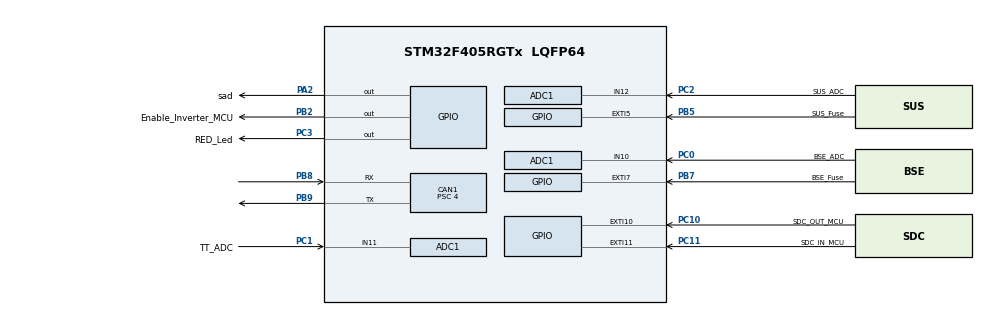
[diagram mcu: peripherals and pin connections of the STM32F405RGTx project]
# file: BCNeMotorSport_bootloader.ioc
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ADC1.Channel-0\#ChannelRegularConversion=ADC_CHANNEL_12
ADC1.Channel-1\#ChannelRegularConversion=ADC_CHANNEL_11
ADC1.Channel-2\#ChannelRegularConversion=ADC_CHANNEL_10
ADC1.ClockPrescaler=ADC_CLOCK_SYNC_PCLK_DIV4
ADC1.ContinuousConvMode=DISABLE
ADC1.DMAContinuousRequests=ENABLE
ADC1.EOCSelection=ADC_EOC_SEQ_CONV
ADC1.ExternalTrigConv=ADC_EXTERNALTRIGCONV_T2_TRGO
ADC1.ExternalTrigConvEdge=ADC_EXTERNALTRIGCONVEDGE_RISINGFALLING
ADC1.NbrOfConversion=3
ADC1.NbrOfConversionFlag=1
ADC1.Rank-0\#ChannelRegularConversion=1
ADC1.Rank-1\#ChannelRegularConversion=2
ADC1.Rank-2\#ChannelRegularConversion=3
ADC1.Resolution=ADC_RESOLUTION_12B
ADC1.SamplingTime-0\#ChannelRegularConversion=ADC_SAMPLETIME_56CYCLES
ADC1.SamplingTime-1\#ChannelRegularConversion=ADC_SAMPLETIME_56CYCLES
ADC1.SamplingTime-2\#ChannelRegularConversion=ADC_SAMPLETIME_56CYCLES
ADC1.master=1
CAN1.BS1=CAN_BS1_5TQ
CAN1.BS2=CAN_BS2_2TQ
CAN1.CalculateBaudRate=250000
CAN1.CalculateTimeBit=4000
CAN1.CalculateTimeQuantum=500.0
CAN1.Prescaler=4
CAN1.SJW=CAN_SJW_2TQ
Dma.ADC1.0.Direction=DMA_PERIPH_TO_MEMORY
Dma.ADC1.0.FIFOMode=DMA_FIFOMODE_DISABLE
Dma.ADC1.0.Instance=DMA2_Stream0
Dma.ADC1.0.MemDataAlignment=DMA_MDATAALIGN_WORD
Dma.ADC1.0.MemInc=DMA_MINC_ENABLE
Dma.ADC1.0.Mode=DMA_CIRCULAR
Dma.ADC1.0.PeriphDataAlignment=DMA_PDATAALIGN_WORD
Dma.ADC1.0.PeriphInc=DMA_PINC_DISABLE
Dma.ADC1.0.Priority=DMA_PRIORITY_LOW
Dma.Request0=ADC1
Mcu.Family=STM32F4
Mcu.Name=STM32F405RGTx
Mcu.Package=LQFP64
NVIC.ADC_IRQn=true\:0\:0\:false\:false\:true\:true\:true\:true
NVIC.CAN1_RX0_IRQn=true\:0\:0\:false\:false\:true\:true\:true\:true
NVIC.CAN1_RX1_IRQn=true\:0\:0\:false\:false\:true\:true\:true\:true
NVIC.CAN1_SCE_IRQn=true\:0\:0\:false\:false\:true\:true\:true\:true
NVIC.CAN1_TX_IRQn=true\:0\:0\:false\:false\:true\:true\:true\:true
NVIC.DMA2_Stream0_IRQn=true\:0\:0\:false\:false\:true\:false\:true\:true
NVIC.EXTI15_10_IRQn=true\:0\:0\:false\:false\:true\:true\:true\:true
NVIC.PriorityGroup=NVIC_PRIORITYGROUP_4
NVIC.RCC_IRQn=true\:0\:0\:false\:false\:true\:true\:false\:true
NVIC.TIM2_IRQn=true\:0\:0\:false\:false\:true\:true\:true\:true
PA13.Mode=Serial_Wire
PA13.Signal=SYS_JTMS-SWDIO
PA14.Mode=Serial_Wire
PA14.Signal=SYS_JTCK-SWCLK
PA2.GPIO_Label=sad
PA2.Signal=GPIO_Output
PB2.GPIO_Label=Enable_Inverter_MCU
PB2.Signal=GPIO_Output
PB5.GPIO_Label=SUS_Fuse
PB5.GPIO_ModeDefaultEXTI=GPIO_MODE_IT_RISING_FALLING
PB5.Signal=GPXTI5
PB7.GPIO_Label=BSE_Fuse
PB7.GPIO_ModeDefaultEXTI=GPIO_MODE_IT_RISING_FALLING
PB7.Signal=GPXTI7
PB8.Mode=CAN_Activate
PB8.Signal=CAN1_RX
PB9.Mode=CAN_Activate
PB9.Signal=CAN1_TX
PC0.GPIO_Label=BSE_ADC
PC0.Signal=ADCx_IN10
PC1.GPIO_Label=TT_ADC
PC1.Signal=ADCx_IN11
PC10.GPIO_Label=SDC_OUT_MCU
PC10.GPIO_ModeDefaultEXTI=GPIO_MODE_IT_RISING_FALLING
PC10.Signal=GPXTI10
PC11.GPIO_Label=SDC_IN_MCU
PC11.GPIO_ModeDefaultEXTI=GPIO_MODE_IT_RISING_FALLING
PC11.Signal=GPXTI11
PC2.GPIO_Label=SUS_ADC
PC2.Signal=ADCx_IN12
PC3.GPIO_Label=RED_Led
PC3.Signal=GPIO_Output
PH0-OSC_IN.Signal=RCC_OSC_IN
PH1-OSC_OUT.Signal=RCC_OSC_OUT
ProjectManager.HeapSize=0x200
ProjectManager.StackSize=0x400
ProjectManager.TargetToolchain=STM32CubeIDE
RCC.48MHZClocksFreq_Value=25600000
RCC.AHBFreq_Value=16000000
RCC.APB1CLKDivider=RCC_HCLK_DIV2
RCC.APB1Freq_Value=8000000
RCC.APB1TimFreq_Value=16000000
RCC.APB2CLKDivider=RCC_HCLK_DIV4
RCC.APB2Freq_Value=4000000
RCC.APB2TimFreq_Value=8000000
RCC.CortexFreq_Value=16000000
RCC.HCLKFreq_Value=16000000
RCC.HSE_VALUE=20000000
RCC.HSI_VALUE=16000000
RCC.LSE_VALUE=32768
RCC.PLLM=10
RCC.PLLN=64
RCC.SYSCLKFreq_VALUE=16000000
RCC.VCOOutputFreq_Value=102400000
SH.ADCx_IN10.0=ADC1_IN10,IN10
SH.ADCx_IN11.0=ADC1_IN11,IN11
SH.ADCx_IN12.0=ADC1_IN12,IN12
TIM2.Channel-Output\ Compare1\ No\ Output=TIM_CHANNEL_1
TIM2.Period=15
TIM2.Prescaler=79
TIM2.TIM_MasterOutputTrigger=TIM_TRGO_UPDATE
VP_TIM2_VS_ClockSourceINT.Mode=Internal
VP_TIM2_VS_no_output1.Mode=Output Compare1 No Output
board=custom

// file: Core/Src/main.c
/* USER CODE BEGIN Header */
/**
  ******************************************************************************
  * @file           : main.c
  * @brief          : Main program body
  ******************************************************************************
  * @attention
  *
  * Copyright (c) 2025 STMicroelectronics.
  * All rights reserved.
  *
  * This software is licensed under terms that can be found in the LICENSE file
  * in the root directory of this software component.
  * If no LICENSE file comes with this software, it is provided AS-IS.
  *
  ******************************************************************************
  */
/* USER CODE END Header */
#include "main.h"

/* USER CODE BEGIN Includes */
#include "boot.h"
/* USER CODE END Includes */

CAN_HandleTypeDef hcan1;

void SystemClock_Config(void);
static void MX_GPIO_Init(void);
static void MX_DMA_Init(void);
static void MX_ADC1_Init(void);
static void MX_CAN1_Init(void);
static void MX_TIM2_Init(void);

int main(void)
{

  /* MCU Configuration--------------------------------------------------------*/

  /* Reset of all peripherals, Initializes the Flash interface and the Systick. */
  HAL_Init();

  /* Configure the system clock */
  SystemClock_Config();

  /* Initialize all configured peripherals */
  MX_GPIO_Init();
  MX_DMA_Init();
  MX_ADC1_Init();
  MX_CAN1_Init();
  MX_TIM2_Init();
  /* USER CODE BEGIN 2 */
  BootInit();
  /* USER CODE END 2 */

  /* Infinite loop */
  /* USER CODE BEGIN WHILE */
  while (1)
  {
	  BootTask();

    /* USER CODE END WHILE */

  }
}

void SystemClock_Config(void)
{
  LL_FLASH_SetLatency(LL_FLASH_LATENCY_0);
  while(LL_FLASH_GetLatency()!= LL_FLASH_LATENCY_0)
  {
  }
  LL_PWR_SetRegulVoltageScaling(LL_PWR_REGU_VOLTAGE_SCALE1);
  LL_RCC_HSI_SetCalibTrimming(16);
  LL_RCC_HSI_Enable();

   /* Wait till HSI is ready */
  while(LL_RCC_HSI_IsReady() != 1)
  {

  }
  LL_RCC_SetAHBPrescaler(LL_RCC_SYSCLK_DIV_1);
  LL_RCC_SetAPB1Prescaler(LL_RCC_APB1_DIV_2);
  LL_RCC_SetAPB2Prescaler(LL_RCC_APB2_DIV_4);
  LL_RCC_SetSysClkSource(LL_RCC_SYS_CLKSOURCE_HSI);

   /* Wait till System clock is ready */
  while(LL_RCC_GetSysClkSource() != LL_RCC_SYS_CLKSOURCE_STATUS_HSI)
  {

  }
  LL_SetSystemCoreClock(16000000);

   /* Update the time base */
  if (HAL_InitTick (TICK_INT_PRIORITY) != HAL_OK)
  {
    Error_Handler();
  }
}

static void MX_ADC1_Init(void)
{

  LL_ADC_InitTypeDef ADC_InitStruct = {0};
  LL_ADC_REG_InitTypeDef ADC_REG_InitStruct = {0};
  LL_ADC_CommonInitTypeDef ADC_CommonInitStruct = {0};

  LL_GPIO_InitTypeDef GPIO_InitStruct = {0};

  /* Peripheral clock enable */
  LL_APB2_GRP1_EnableClock(LL_APB2_GRP1_PERIPH_ADC1);

  LL_AHB1_GRP1_EnableClock(LL_AHB1_GRP1_PERIPH_GPIOC);
  /**ADC1 GPIO Configuration
  PC0   ------> ADC1_IN10
  PC1   ------> ADC1_IN11
  PC2   ------> ADC1_IN12
  */
  GPIO_InitStruct.Pin = BSE_ADC_Pin|TT_ADC_Pin|SUS_ADC_Pin;
  GPIO_InitStruct.Mode = LL_GPIO_MODE_ANALOG;
  GPIO_InitStruct.Pull = LL_GPIO_PULL_NO;
  LL_GPIO_Init(GPIOC, &GPIO_InitStruct);

  /* ADC1 DMA Init */

  /* ADC1 Init */
  LL_DMA_SetChannelSelection(DMA2, LL_DMA_STREAM_0, LL_DMA_CHANNEL_0);

  LL_DMA_SetDataTransferDirection(DMA2, LL_DMA_STREAM_0, LL_DMA_DIRECTION_PERIPH_TO_MEMORY);

  LL_DMA_SetStreamPriorityLevel(DMA2, LL_DMA_STREAM_0, LL_DMA_PRIORITY_LOW);

  LL_DMA_SetMode(DMA2, LL_DMA_STREAM_0, LL_DMA_MODE_CIRCULAR);

  LL_DMA_SetPeriphIncMode(DMA2, LL_DMA_STREAM_0, LL_DMA_PERIPH_NOINCREMENT);

  LL_DMA_SetMemoryIncMode(DMA2, LL_DMA_STREAM_0, LL_DMA_MEMORY_INCREMENT);

  LL_DMA_SetPeriphSize(DMA2, LL_DMA_STREAM_0, LL_DMA_PDATAALIGN_WORD);

  LL_DMA_SetMemorySize(DMA2, LL_DMA_STREAM_0, LL_DMA_MDATAALIGN_WORD);

  LL_DMA_DisableFifoMode(DMA2, LL_DMA_STREAM_0);

  /* ADC1 interrupt Init */
  NVIC_SetPriority(ADC_IRQn, NVIC_EncodePriority(NVIC_GetPriorityGrouping(),0, 0));
  NVIC_EnableIRQ(ADC_IRQn);

  /** Common config
  */
  ADC_InitStruct.Resolution = LL_ADC_RESOLUTION_12B;
  ADC_InitStruct.DataAlignment = LL_ADC_DATA_ALIGN_RIGHT;
  ADC_InitStruct.SequencersScanMode = LL_ADC_SEQ_SCAN_ENABLE;
  LL_ADC_Init(ADC1, &ADC_InitStruct);
  ADC_REG_InitStruct.TriggerSource = LL_ADC_REG_TRIG_EXT_TIM2_TRGO;
  ADC_REG_InitStruct.SequencerLength = LL_ADC_REG_SEQ_SCAN_ENABLE_3RANKS;
  ADC_REG_InitStruct.SequencerDiscont = LL_ADC_REG_SEQ_DISCONT_DISABLE;
  ADC_REG_InitStruct.ContinuousMode = LL_ADC_REG_CONV_SINGLE;
  ADC_REG_InitStruct.DMATransfer = LL_ADC_REG_DMA_TRANSFER_UNLIMITED;
  LL_ADC_REG_Init(ADC1, &ADC_REG_InitStruct);
  LL_ADC_REG_SetFlagEndOfConversion(ADC1, LL_ADC_REG_FLAG_EOC_SEQUENCE_CONV);
  ADC_CommonInitStruct.CommonClock = LL_ADC_CLOCK_SYNC_PCLK_DIV4;
  ADC_CommonInitStruct.Multimode = LL_ADC_MULTI_INDEPENDENT;
  LL_ADC_CommonInit(__LL_ADC_COMMON_INSTANCE(ADC1), &ADC_CommonInitStruct);
  LL_ADC_REG_StartConversionExtTrig(ADC1, LL_ADC_REG_TRIG_EXT_RISINGFALLING);

  /** Configure Regular Channel
  */
  LL_ADC_REG_SetSequencerRanks(ADC1, LL_ADC_REG_RANK_1, LL_ADC_CHANNEL_12);
  LL_ADC_SetChannelSamplingTime(ADC1, LL_ADC_CHANNEL_12, LL_ADC_SAMPLINGTIME_56CYCLES);

  /** Configure Regular Channel
  */
  LL_ADC_REG_SetSequencerRanks(ADC1, LL_ADC_REG_RANK_2, LL_ADC_CHANNEL_11);
  LL_ADC_SetChannelSamplingTime(ADC1, LL_ADC_CHANNEL_11, LL_ADC_SAMPLINGTIME_56CYCLES);

  /** Configure Regular Channel
  */
  LL_ADC_REG_SetSequencerRanks(ADC1, LL_ADC_REG_RANK_3, LL_ADC_CHANNEL_10);
  LL_ADC_SetChannelSamplingTime(ADC1, LL_ADC_CHANNEL_10, LL_ADC_SAMPLINGTIME_56CYCLES);

}

static void MX_CAN1_Init(void)
{

  hcan1.Instance = CAN1;
  hcan1.Init.Prescaler = 4;
  hcan1.Init.Mode = CAN_MODE_NORMAL;
  hcan1.Init.SyncJumpWidth = CAN_SJW_2TQ;
  hcan1.Init.TimeSeg1 = CAN_BS1_5TQ;
  hcan1.Init.TimeSeg2 = CAN_BS2_2TQ;
  hcan1.Init.TimeTriggeredMode = DISABLE;
  hcan1.Init.AutoBusOff = DISABLE;
  hcan1.Init.AutoWakeUp = DISABLE;
  hcan1.Init.AutoRetransmission = DISABLE;
  hcan1.Init.ReceiveFifoLocked = DISABLE;
  hcan1.Init.TransmitFifoPriority = DISABLE;
  if (HAL_CAN_Init(&hcan1) != HAL_OK)
  {
    Error_Handler();
  }

}

static void MX_TIM2_Init(void)
{

  LL_TIM_InitTypeDef TIM_InitStruct = {0};
  LL_TIM_OC_InitTypeDef TIM_OC_InitStruct = {0};

  /* Peripheral clock enable */
  LL_APB1_GRP1_EnableClock(LL_APB1_GRP1_PERIPH_TIM2);

  /* TIM2 interrupt Init */
  NVIC_SetPriority(TIM2_IRQn, NVIC_EncodePriority(NVIC_GetPriorityGrouping(),0, 0));
  NVIC_EnableIRQ(TIM2_IRQn);

  TIM_InitStruct.Prescaler = 79;
  TIM_InitStruct.CounterMode = LL_TIM_COUNTERMODE_UP;
  TIM_InitStruct.Autoreload = 15;
  TIM_InitStruct.ClockDivision = LL_TIM_CLOCKDIVISION_DIV1;
  LL_TIM_Init(TIM2, &TIM_InitStruct);
  LL_TIM_DisableARRPreload(TIM2);
  LL_TIM_SetClockSource(TIM2, LL_TIM_CLOCKSOURCE_INTERNAL);
  TIM_OC_InitStruct.OCMode = LL_TIM_OCMODE_FROZEN;
  TIM_OC_InitStruct.OCState = LL_TIM_OCSTATE_DISABLE;
  TIM_OC_InitStruct.OCNState = LL_TIM_OCSTATE_DISABLE;
  TIM_OC_InitStruct.CompareValue = 0;
  TIM_OC_InitStruct.OCPolarity = LL_TIM_OCPOLARITY_HIGH;
  LL_TIM_OC_Init(TIM2, LL_TIM_CHANNEL_CH1, &TIM_OC_InitStruct);
  LL_TIM_OC_DisableFast(TIM2, LL_TIM_CHANNEL_CH1);
  LL_TIM_SetTriggerOutput(TIM2, LL_TIM_TRGO_UPDATE);
  LL_TIM_DisableMasterSlaveMode(TIM2);

}

static void MX_DMA_Init(void)
{

  /* Init with LL driver */
  /* DMA controller clock enable */
  LL_AHB1_GRP1_EnableClock(LL_AHB1_GRP1_PERIPH_DMA2);

  /* DMA interrupt init */
  /* DMA2_Stream0_IRQn interrupt configuration */
  NVIC_SetPriority(DMA2_Stream0_IRQn, NVIC_EncodePriority(NVIC_GetPriorityGrouping(),0, 0));
  NVIC_EnableIRQ(DMA2_Stream0_IRQn);

}

static void MX_GPIO_Init(void)
{
  LL_EXTI_InitTypeDef EXTI_InitStruct = {0};
  LL_GPIO_InitTypeDef GPIO_InitStruct = {0};

  /* GPIO Ports Clock Enable */
  LL_AHB1_GRP1_EnableClock(LL_AHB1_GRP1_PERIPH_GPIOH);
  LL_AHB1_GRP1_EnableClock(LL_AHB1_GRP1_PERIPH_GPIOC);
  LL_AHB1_GRP1_EnableClock(LL_AHB1_GRP1_PERIPH_GPIOA);
  LL_AHB1_GRP1_EnableClock(LL_AHB1_GRP1_PERIPH_GPIOB);

  /**/
  LL_GPIO_ResetOutputPin(RED_Led_GPIO_Port, RED_Led_Pin);

  /**/
  LL_GPIO_ResetOutputPin(sad_GPIO_Port, sad_Pin);

  /**/
  LL_GPIO_ResetOutputPin(Enable_Inverter_MCU_GPIO_Port, Enable_Inverter_MCU_Pin);

  /**/
  GPIO_InitStruct.Pin = RED_Led_Pin;
  GPIO_InitStruct.Mode = LL_GPIO_MODE_OUTPUT;
  GPIO_InitStruct.Speed = LL_GPIO_SPEED_FREQ_LOW;
  GPIO_InitStruct.OutputType = LL_GPIO_OUTPUT_PUSHPULL;
  GPIO_InitStruct.Pull = LL_GPIO_PULL_NO;
  LL_GPIO_Init(RED_Led_GPIO_Port, &GPIO_InitStruct);

  /**/
  GPIO_InitStruct.Pin = sad_Pin;
  GPIO_InitStruct.Mode = LL_GPIO_MODE_OUTPUT;
  GPIO_InitStruct.Speed = LL_GPIO_SPEED_FREQ_LOW;
  GPIO_InitStruct.OutputType = LL_GPIO_OUTPUT_PUSHPULL;
  GPIO_InitStruct.Pull = LL_GPIO_PULL_NO;
  LL_GPIO_Init(sad_GPIO_Port, &GPIO_InitStruct);

  /**/
  GPIO_InitStruct.Pin = Enable_Inverter_MCU_Pin;
  GPIO_InitStruct.Mode = LL_GPIO_MODE_OUTPUT;
  GPIO_InitStruct.Speed = LL_GPIO_SPEED_FREQ_LOW;
  GPIO_InitStruct.OutputType = LL_GPIO_OUTPUT_PUSHPULL;
  GPIO_InitStruct.Pull = LL_GPIO_PULL_NO;
  LL_GPIO_Init(Enable_Inverter_MCU_GPIO_Port, &GPIO_InitStruct);

  /**/
  LL_SYSCFG_SetEXTISource(LL_SYSCFG_EXTI_PORTC, LL_SYSCFG_EXTI_LINE10);

  /**/
  LL_SYSCFG_SetEXTISource(LL_SYSCFG_EXTI_PORTC, LL_SYSCFG_EXTI_LINE11);

  /**/
  LL_SYSCFG_SetEXTISource(LL_SYSCFG_EXTI_PORTB, LL_SYSCFG_EXTI_LINE5);

  /**/
  LL_SYSCFG_SetEXTISource(LL_SYSCFG_EXTI_PORTB, LL_SYSCFG_EXTI_LINE7);

  /**/
  EXTI_InitStruct.Line_0_31 = LL_EXTI_LINE_10;
  EXTI_InitStruct.LineCommand = ENABLE;
  EXTI_InitStruct.Mode = LL_EXTI_MODE_IT;
  EXTI_InitStruct.Trigger = LL_EXTI_TRIGGER_RISING_FALLING;
  LL_EXTI_Init(&EXTI_InitStruct);

  /**/
  EXTI_InitStruct.Line_0_31 = LL_EXTI_LINE_11;
  EXTI_InitStruct.LineCommand = ENABLE;
  EXTI_InitStruct.Mode = LL_EXTI_MODE_IT;
  EXTI_InitStruct.Trigger = LL_EXTI_TRIGGER_RISING_FALLING;
  LL_EXTI_Init(&EXTI_InitStruct);

  /**/
  EXTI_InitStruct.Line_0_31 = LL_EXTI_LINE_5;
  EXTI_InitStruct.LineCommand = ENABLE;
  EXTI_InitStruct.Mode = LL_EXTI_MODE_IT;
  EXTI_InitStruct.Trigger = LL_EXTI_TRIGGER_RISING_FALLING;
  LL_EXTI_Init(&EXTI_InitStruct);

  /**/
  EXTI_InitStruct.Line_0_31 = LL_EXTI_LINE_7;
  EXTI_InitStruct.LineCommand = ENABLE;
  EXTI_InitStruct.Mode = LL_EXTI_MODE_IT;
  EXTI_InitStruct.Trigger = LL_EXTI_TRIGGER_RISING_FALLING;
  LL_EXTI_Init(&EXTI_InitStruct);

  /**/
  LL_GPIO_SetPinPull(SDC_OUT_MCU_GPIO_Port, SDC_OUT_MCU_Pin, LL_GPIO_PULL_NO);

  /**/
  LL_GPIO_SetPinPull(SDC_IN_MCU_GPIO_Port, SDC_IN_MCU_Pin, LL_GPIO_PULL_NO);

  /**/
  LL_GPIO_SetPinPull(SUS_Fuse_GPIO_Port, SUS_Fuse_Pin, LL_GPIO_PULL_NO);

  /**/
  LL_GPIO_SetPinPull(BSE_Fuse_GPIO_Port, BSE_Fuse_Pin, LL_GPIO_PULL_NO);

  /**/
  LL_GPIO_SetPinMode(SDC_OUT_MCU_GPIO_Port, SDC_OUT_MCU_Pin, LL_GPIO_MODE_INPUT);

  /**/
  LL_GPIO_SetPinMode(SDC_IN_MCU_GPIO_Port, SDC_IN_MCU_Pin, LL_GPIO_MODE_INPUT);

  /**/
  LL_GPIO_SetPinMode(SUS_Fuse_GPIO_Port, SUS_Fuse_Pin, LL_GPIO_MODE_INPUT);

  /**/
  LL_GPIO_SetPinMode(BSE_Fuse_GPIO_Port, BSE_Fuse_Pin, LL_GPIO_MODE_INPUT);

  /* EXTI interrupt init*/
  NVIC_SetPriority(EXTI15_10_IRQn, NVIC_EncodePriority(NVIC_GetPriorityGrouping(),0, 0));
  NVIC_EnableIRQ(EXTI15_10_IRQn);

}

void Error_Handler(void)
{
  __disable_irq();
  while (1)
  {
  }
}
